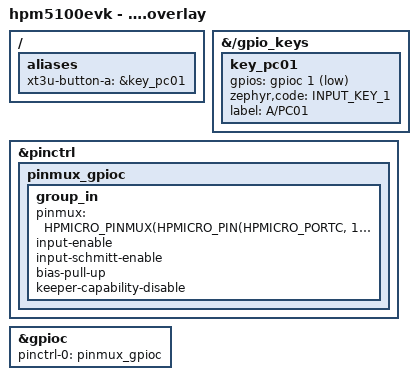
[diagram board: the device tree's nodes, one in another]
/*
 * Copyright 2026 HPMicro
 * SPDX-License-Identifier: Apache-2.0
 *
 * xT3U A button (PC01) via Zephyr GPIO0. B/X/Y and dpad stay on HPM SDK FGPIO
 * in src/main.c (same split as xt3u_buttons.c).
 *
 * west build -b hpm5100evk sdk_glue/samples/drivers/test_io -d build_hpm5100evk_test_io
 */

#include <zephyr/dt-bindings/input/input-event-codes.h>
#include <zephyr/dt-bindings/gpio/gpio.h>
#include <dt-bindings/pinctrl/hpmicro-pinctrl-common.h>

/ {
	aliases {
		xt3u-button-a = &key_pc01;
	};
};

&{/gpio_keys} {
	key_pc01: key_pc01 {
		gpios = <&gpioc 1 (GPIO_PULL_UP | GPIO_ACTIVE_LOW)>;
		zephyr,code = <INPUT_KEY_1>;
		label = "A/PC01";
	};
};

&pinctrl {
	pinmux_gpioc: pinmux_gpioc {
		group_in {
			pinmux = <HPMICRO_PINMUX(HPMICRO_PIN(HPMICRO_PORTC, 1), IOC_TYPE_IOC, 0, 0)>;
			input-enable;
			input-schmitt-enable;
			bias-pull-up;
			keeper-capability-disable;
		};
	};
};

&gpioc {
	pinctrl-0 = <&pinmux_gpioc>;
	pinctrl-names = "default";
	status = "okay";
};
